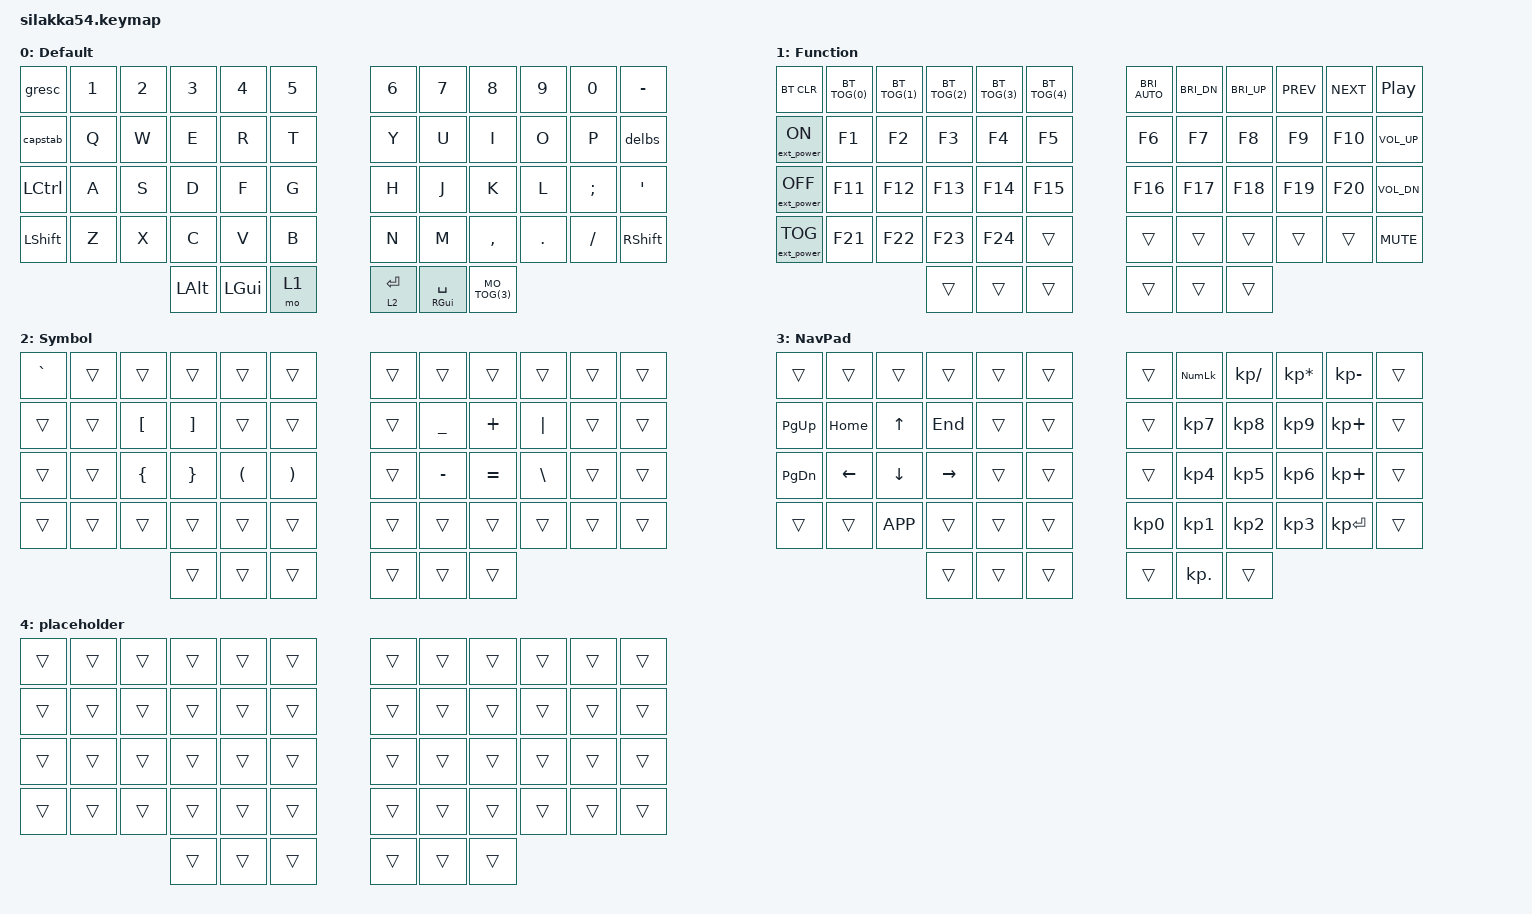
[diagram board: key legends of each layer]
/*
 * Default Silakka54 keymap.
 */

#include <behaviors.dtsi>
#include <dt-bindings/zmk/keys.h>
#include <dt-bindings/zmk/bt.h>
#include <dt-bindings/zmk/ext_power.h>

#define MO_TOG(layer) &mo_tog layer layer
#define BT_TOG(number) &bt_tog number number

&gresc {
    mods = <(MOD_LGUI|MOD_RSFT)>;
    keep-mods = <(MOD_LGUI|MOD_RSFT)>;
};

/ {
    macros {
        bt_s: bt_select {
            compatible = "zmk,behavior-macro-one-param";
            #binding-cells = <1>;
            bindings= <&macro_param_1to2>, <&bt BT_SEL MACRO_PLACEHOLDER>;
        };
        bt_d: bt_disconnect {
            compatible = "zmk,behavior-macro-one-param";
            #binding-cells = <1>;
            bindings= <&macro_param_1to2>, <&bt BT_DISC MACRO_PLACEHOLDER>;
        };
    };
    behaviors {
        bmt: balanced_mod_tap {
            compatible = "zmk,behavior-hold-tap";
            #binding-cells = <2>;
            flavor = "balanced";
            tapping-term-ms = <200>;
            bindings = <&kp>, <&kp>;
            display-name = "BMod-Tap";
        };
        capstab: capslock_tab {
            compatible = "zmk,behavior-mod-morph";
            #binding-cells = <0>;
            bindings = <&kp TAB>, <&kp CAPS>;
            mods = <(MOD_RSFT)>;
        };
        delbs: delete_backspace {
            compatible = "zmk,behavior-mod-morph";
            #binding-cells = <0>;
            bindings = <&kp BSPC>, <&kp DEL>;
            mods = <(MOD_RSFT)>;
        };
        mo_tog: behavior_mo_tog {
            compatible = "zmk,behavior-hold-tap";
            #binding-cells = <2>;
            flavor = "hold-preferred";
            tapping-term-ms = <200>;
            bindings = <&mo>, <&tog>;
        };
        bt_tog: behavior_bluetooth_tog {
            compatible = "zmk,behavior-hold-tap";
            #binding-cells = <2>;
            flavor = "balanced";
            tapping-term-ms = <200>;
            bindings = <&bt_d>, <&bt_s>;
        };
    };
    keymap {
        compatible = "zmk,keymap";

        default_layer {
            display-name = "Default";
// ----------------------------------------------------------------------------------------------------
// | `ESC  |  1  |  2  |  3   |  4   |  5   |           |  6   |  7   |  8   |  9   |   0   |   -   |
// |  TAB  |  Q  |  W  |  E   |  R   |  T   |           |  Y   |  U   |  I   |  O   |   P   |  BSPC |
// |  CTRL |  A  |  S  |  D   |  F   |  G   |           |  H   |  J   |  K   |  L   |   ;   |   '   |
// | SHIFT |  Z  |  X  |  C   |  V   |  B   |           |  N   |  M   |  ,   |  .   |   /   | SHIFT |
//                     | ALT  | GUI  | LOWER|           | ENTER| SPACE| RAISE|
            bindings = <
&gresc    &kp N1 &kp N2 &kp N3   &kp N4   &kp N5        &kp N6    &kp N7          &kp N8    &kp N9  &kp N0   &kp MINUS
&capstab  &kp Q  &kp W  &kp E    &kp R    &kp T         &kp Y     &kp U           &kp I     &kp O   &kp P    &delbs
&kp LCTRL &kp A  &kp S  &kp D    &kp F    &kp G         &kp H     &kp J           &kp K     &kp L   &kp SEMI &kp SQT
&kp LSHFT &kp Z  &kp X  &kp C    &kp V    &kp B         &kp N     &kp M           &kp COMMA &kp DOT &kp FSLH &kp RSHFT
                        &kp LALT &kp LGUI &mo 1         &lt 2 RET &bmt RGUI SPACE MO_TOG(3)
            >;
        };

        function_layer {
            display-name = "Function";
            bindings = <
&bt BT_CLR        BT_TOG(0) BT_TOG(1) BT_TOG(2) BT_TOG(3) BT_TOG(4)     &kp C_BRI_AUTO &kp C_BRI_DN &kp C_BRI_UP &kp C_PREV &kp C_NEXT &kp C_PP
&ext_power EP_ON  &kp F1    &kp F2    &kp F3    &kp F4    &kp F5        &kp F6         &kp F7       &kp F8       &kp F9     &kp F10  &kp C_VOL_UP
&ext_power EP_OFF &kp F11   &kp F12   &kp F13   &kp F14   &kp F15       &kp F16        &kp F17      &kp F18      &kp F19    &kp F20  &kp C_VOL_DN
&ext_power EP_TOG &kp F21   &kp F22   &kp F23   &kp F24   &trans        &trans         &trans       &trans       &trans     &trans   &kp C_MUTE
                                      &trans    &trans    &trans        &trans         &trans       &trans
            >;
        };

        symbol_layer {
            display-name = "Symbol";
            bindings = <
&kp GRAVE &trans &trans   &trans   &trans   &trans        &trans &trans    &trans    &trans   &trans &trans
&trans    &trans &kp LBKT &kp RBKT &trans   &trans        &trans &kp UNDER &kp PLUS  &kp PIPE &trans &trans
&trans    &trans &kp LBRC &kp RBRC &kp LPAR &kp RPAR      &trans &kp MINUS &kp EQUAL &kp BSLH &trans &trans
&trans    &trans &trans   &trans   &trans   &trans        &trans &trans    &trans    &trans   &trans &trans
                          &trans   &trans   &trans        &trans &trans    &trans
            >;
        };

        navigation_keypad_layer {
            display-name = "NavPad";
            bindings = <
&trans    &trans   &trans    &trans    &trans &trans    &trans    &kp KP_NLCK &kp KP_DIVIDE &kp KP_MULTIPLY &kp KP_MINUS &trans
&kp PG_UP &kp HOME &kp UP    &kp END   &trans &trans    &trans    &kp KP_N7   &kp KP_N8     &kp KP_N9       &kp KP_PLUS  &trans
&kp PG_DN &kp LEFT &kp DOWN  &kp RIGHT &trans &trans    &trans    &kp KP_N4   &kp KP_N5     &kp KP_N6       &kp KP_PLUS  &trans
&trans    &trans   &kp K_APP &trans    &trans &trans    &kp KP_N0 &kp KP_N1   &kp KP_N2     &kp KP_N3       &kp KP_ENTER &trans
                             &trans    &trans &trans    &trans    &kp KP_DOT  &trans
            >;
        };

        placeholder {
            bindings = <
&trans &trans &trans &trans &trans &trans   &trans &trans &trans &trans &trans &trans
&trans &trans &trans &trans &trans &trans   &trans &trans &trans &trans &trans &trans
&trans &trans &trans &trans &trans &trans   &trans &trans &trans &trans &trans &trans
&trans &trans &trans &trans &trans &trans   &trans &trans &trans &trans &trans &trans
                     &trans &trans &trans   &trans &trans &trans
            >;
        };
    };
};
